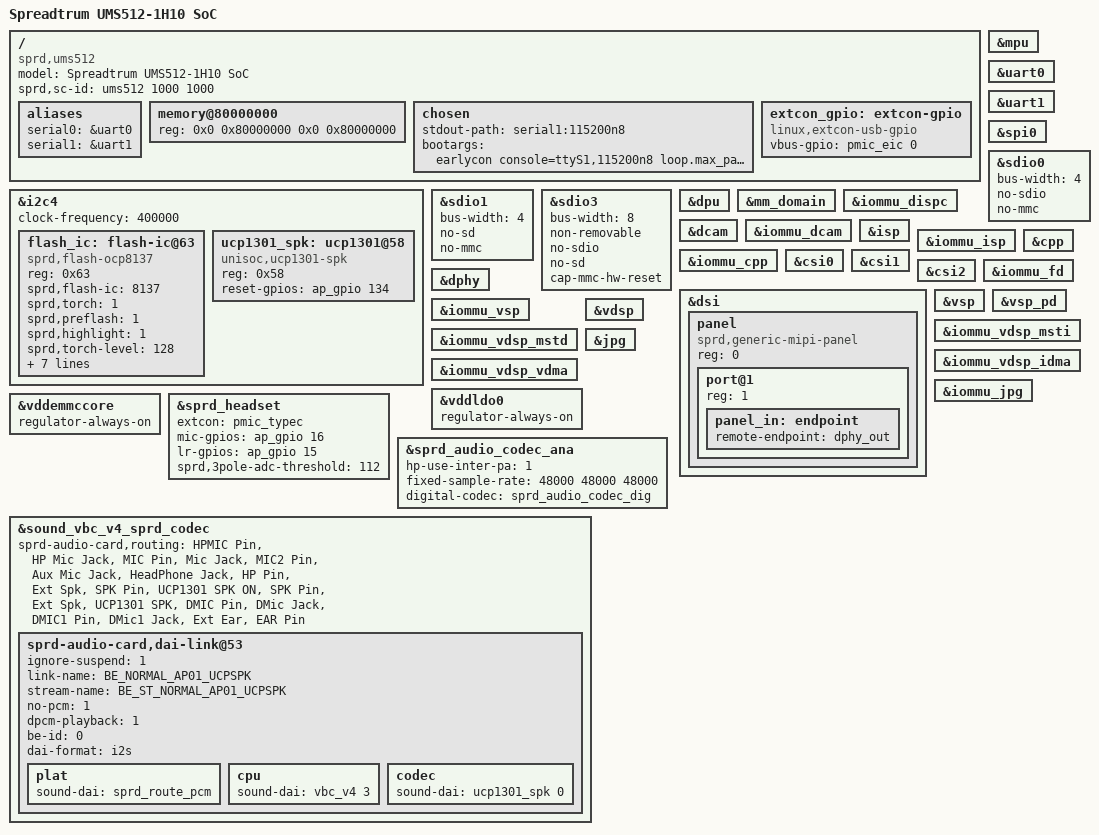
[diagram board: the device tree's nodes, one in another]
// SPDX-License-Identifier: GPL-2.0-only
/*
 * Unisoc UMS512-1h10 boards DTS file
 *
 * Copyright (C) 2020, Unisoc Inc.
 */

/dts-v1/;

#include <dt-bindings/gpio/gpio.h>
#include "ums512.dtsi"
#include "sc2730.dtsi"
#include "sprd-sound-fe-be.dtsi"
#include "ums512-mach.dtsi"

/ {
	model = "Spreadtrum UMS512-1H10 SoC";

	compatible = "sprd,ums512";

	sprd,sc-id = "ums512 1000 1000";

	aliases {
		serial0 = &uart0;
		serial1 = &uart1;
	};

	memory@80000000 {
		device_type = "memory";
		reg = <0x0 0x80000000 0x0 0x80000000>;
	};

	chosen: chosen {
		stdout-path = "serial1:115200n8";
		bootargs = "earlycon console=ttyS1,115200n8 loop.max_part=7 loglevel=1 init=/init root=/dev/ram0 rw printk.devkmsg=on androidboot.boot_devices=soc/soc:ap-apb/71400000.sdio dummy_hcd.num=0 swiotlb=1 initcall_debug=1 androidboot.init_fatal_panic=true";
	};

	extcon_gpio: extcon-gpio {
		compatible = "linux,extcon-usb-gpio";
		vbus-gpio = <&pmic_eic 0 GPIO_ACTIVE_HIGH>;
	};
};

&mpu {
	status = "okay";
};

&uart0 {
	status = "okay";
};

&uart1 {
	status = "okay";
};

&i2c4 {
	status = "okay";
	clock-frequency = <400000>;

	flash_ic: flash-ic@63 {
		compatible = "sprd,flash-ocp8137";
		reg = <0x63>;
		sprd,flash-ic = <8137>;
		sprd,torch = <1>;
		sprd,preflash = <1>;
		sprd,highlight = <1>;
		sprd,torch-level = <128>;
		sprd,preflash-level = <128>;
		sprd,highlight-level = <128>;
		sprd,lvfm-enable = <1>;
		flash-chip-en-gpios = <&ap_gpio 136 0>;
		flash-torch-en-gpios = <&ap_gpio 139 0>;
		flash-en-gpios = <&ap_gpio 137 0>;
		flash-sync-gpios = <&ap_gpio 138 0>;
	};

	ucp1301_spk: ucp1301@58 {
		compatible = "unisoc,ucp1301-spk";
		reg = <0x58>;
		reset-gpios = <&ap_gpio 134 GPIO_ACTIVE_HIGH>;
		#sound-dai-cells = <1>;
	};
};

&spi0 {
	/*used for fingerprint sensor*/
	status = "okay";
};

&sdio0 {
	bus-width = <4>;
	no-sdio;
	no-mmc;
	status = "okay";
};

&sdio1 {
	bus-width = <4>;
	no-sd;
	no-mmc;
	status = "okay";
};

&sdio3 {
	bus-width = <8>;
	non-removable;
	no-sdio;
	no-sd;
	cap-mmc-hw-reset;
	status = "okay";
};

&dpu {
	status = "okay";
};

&mm_domain {
	status = "okay";
};

&iommu_dispc {
	status = "okay";
};

&dcam {
	status = "okay";
};

&iommu_dcam {
	status = "okay";
};

&isp {
	status = "okay";
};

&iommu_isp {
	status = "okay";
};

&cpp {
	status = "okay";
};

&iommu_cpp {
	status = "okay";
};

&csi0 {
	status = "okay";
};

&csi1 {
	status = "okay";
};

&csi2 {
	status = "okay";
};

&iommu_fd {
	status = "okay";
};

&dsi {
	status = "okay";
	#address-cells = <1>;
	#size-cells = <0>;

	panel: panel {
		compatible = "sprd,generic-mipi-panel";
		#address-cells = <1>;
		#size-cells = <0>;
		reg = <0>;

		port@1 {
			reg = <1>;
			panel_in: endpoint {
				remote-endpoint = <&dphy_out>;
			};
		};
	};
};

&dphy {
	status = "okay";
};

&vsp {
	status = "okay";
};

&vsp_pd {
	status = "okay";
};

&iommu_vsp {
	status = "okay";
};

&iommu_vdsp_msti {
	status = "okay";
};

&iommu_vdsp_mstd {
	status = "okay";
};

&iommu_vdsp_idma {
	status = "okay";
};

&iommu_vdsp_vdma {
	status = "okay";
};

&vdsp {
	status = "okay";
};

&jpg {
	status = "okay";
};

&iommu_jpg {
	status = "okay";
};

&vddldo0 {
	regulator-always-on;
};

&vddemmccore {
	regulator-always-on;
};

&sprd_headset {
	status = "okay";
	extcon = <&pmic_typec>;
	mic-gpios = <&ap_gpio 16 GPIO_ACTIVE_HIGH>;
	lr-gpios = <&ap_gpio 15 GPIO_ACTIVE_HIGH>;
	sprd,3pole-adc-threshold = <112>;
};

&sprd_audio_codec_ana {
	status = "okay";
	hp-use-inter-pa = <1>;
	fixed-sample-rate = <48000 48000 48000>;
	digital-codec = <&sprd_audio_codec_dig>;
};

&sound_vbc_v4_sprd_codec {
	status = "okay";
	sprd-audio-card,routing =
		"HPMIC Pin", "HP Mic Jack",
		"MIC Pin", "Mic Jack",
		"MIC2 Pin", "Aux Mic Jack",
		"HeadPhone Jack", "HP Pin",
		"Ext Spk", "SPK Pin",
		"UCP1301 SPK ON", "SPK Pin",
		"Ext Spk", "UCP1301 SPK",
		"DMIC Pin", "DMic Jack",
		"DMIC1 Pin", "DMic1 Jack",
		"Ext Ear", "EAR Pin";

	/* 35: ucp1301 normal ap01 */
	sprd-audio-card,dai-link@53 {
		ignore-suspend = <1>;
		link-name = "BE_NORMAL_AP01_UCPSPK";
		stream-name = "BE_ST_NORMAL_AP01_UCPSPK";
		no-pcm = <1>;
		dpcm-playback = <1>;
		be-id = <0>;
		dai-format = "i2s";
		plat {
			sound-dai = <&sprd_route_pcm>;
		};
		cpu {
			sound-dai = <&vbc_v4 3>;
		};
		codec {
			sound-dai = <&ucp1301_spk 0>;
		};
	};

	/*
	 * node 54 and node 55 (index 36 and 37) are reserved for
	 * "ucp1301-spk2" and "ucp1301-rcv"
	 * nodes from 56 to 67 (index from 38 to 49) are used by HIFI
	 */
};
